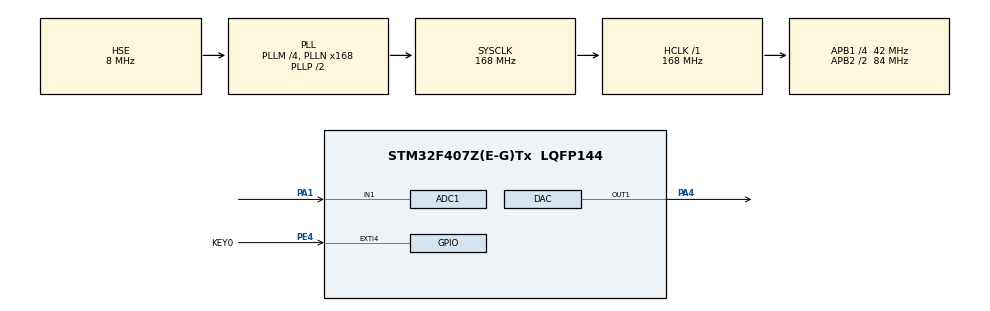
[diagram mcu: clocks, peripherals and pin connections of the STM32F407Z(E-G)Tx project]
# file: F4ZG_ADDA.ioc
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ADC1.Channel-5\#ChannelRegularConversion=ADC_CHANNEL_1
ADC1.NbrOfConversionFlag=1
ADC1.Rank-5\#ChannelRegularConversion=1
ADC1.SamplingTime-5\#ChannelRegularConversion=ADC_SAMPLETIME_3CYCLES
ADC1.master=1
Mcu.Family=STM32F4
Mcu.Name=STM32F407Z(E-G)Tx
Mcu.Package=LQFP144
NVIC.PriorityGroup=NVIC_PRIORITYGROUP_4
PA1.Signal=ADCx_IN1
PA13.Mode=Serial_Wire
PA13.Signal=SYS_JTMS-SWDIO
PA14.Mode=Serial_Wire
PA14.Signal=SYS_JTCK-SWCLK
PA4.Signal=COMP_DAC1_group
PE4.GPIO_Label=KEY0
PE4.GPIO_ModeDefaultEXTI=GPIO_MODE_IT_FALLING
PE4.GPIO_PuPd=GPIO_PULLUP
PE4.Signal=GPXTI4
PH0-OSC_IN.Mode=HSE-External-Oscillator
PH0-OSC_IN.Signal=RCC_OSC_IN
PH1-OSC_OUT.Mode=HSE-External-Oscillator
PH1-OSC_OUT.Signal=RCC_OSC_OUT
ProjectManager.HeapSize=0x200
ProjectManager.StackSize=0x400
ProjectManager.TargetToolchain=MDK-ARM V5
RCC.48MHZClocksFreq_Value=84000000
RCC.AHBFreq_Value=168000000
RCC.APB1CLKDivider=RCC_HCLK_DIV4
RCC.APB1Freq_Value=42000000
RCC.APB1TimFreq_Value=84000000
RCC.APB2CLKDivider=RCC_HCLK_DIV2
RCC.APB2Freq_Value=84000000
RCC.APB2TimFreq_Value=168000000
RCC.CortexFreq_Value=168000000
RCC.HCLKFreq_Value=168000000
RCC.HSE_VALUE=8000000
RCC.HSI_VALUE=16000000
RCC.PLLM=4
RCC.PLLN=168
RCC.PLLSourceVirtual=RCC_PLLSOURCE_HSE
RCC.SYSCLKFreq_VALUE=168000000
RCC.SYSCLKSource=RCC_SYSCLKSOURCE_PLLCLK
RCC.VCOOutputFreq_Value=336000000
SH.ADCx_IN1.0=ADC1_IN1,IN1
SH.COMP_DAC1_group.0=DAC_OUT1,DAC_OUT1
TIM2.Period=9
TIM2.Prescaler=20
VP_TIM2_VS_ClockSourceINT.Mode=Internal
board=custom

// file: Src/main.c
/* USER CODE BEGIN Header */
/**
  ******************************************************************************
  * @file           : main.c
  * @brief          : Main program body
  ******************************************************************************
  * @attention
  *
  * <h2><center>&copy; Copyright (c) 2021 STMicroelectronics.
  * All rights reserved.</center></h2>
  *
  * This software component is licensed by ST under BSD 3-Clause license,
  * the "License"; You may not use this file except in compliance with the
  * License. You may obtain a copy of the License at:
  *                        opensource.org/licenses/BSD-3-Clause
  *
  ******************************************************************************
  */
/* USER CODE END Header */

#include "main.h"
#include "adc.h"
#include "dac.h"
#include "tim.h"
#include "gpio.h"

void SystemClock_Config(void);

/* USER CODE BEGIN 0 */
uint32_t AD_1;

/* USER CODE END 0 */

int main(void)
{

  /* MCU Configuration--------------------------------------------------------*/

  /* Reset of all peripherals, Initializes the Flash interface and the Systick. */
  HAL_Init();

  /* Configure the system clock */
  SystemClock_Config();

  /* Initialize all configured peripherals */
  MX_GPIO_Init();
  MX_ADC1_Init();
  MX_DAC_Init();
  MX_TIM2_Init();
  /* USER CODE BEGIN 2 */
HAL_ADC_Start(&hadc1); //??ADC??
HAL_DAC_Start(&hdac,DAC_CHANNEL_1); //??DAC??

//HAL_ADC_Start_DMA(&hadc1,(uint32_t*)AD_1,1);
  /* USER CODE END 2 */

  /* Infinite loop */
  while (1)
  {

        AD_1 = get_AD1();
        HAL_Delay(500);
    /* USER CODE BEGIN */
  }
  /* USER CODE END 3 */
}

void SystemClock_Config(void)
{
  RCC_OscInitTypeDef RCC_OscInitStruct = {0};
  RCC_ClkInitTypeDef RCC_ClkInitStruct = {0};

  /** Configure the main internal regulator output voltage
  */
  __HAL_RCC_PWR_CLK_ENABLE();
  __HAL_PWR_VOLTAGESCALING_CONFIG(PWR_REGULATOR_VOLTAGE_SCALE1);
  /** Initializes the CPU, AHB and APB busses clocks
  */
  RCC_OscInitStruct.OscillatorType = RCC_OSCILLATORTYPE_HSE;
  RCC_OscInitStruct.HSEState = RCC_HSE_ON;
  RCC_OscInitStruct.PLL.PLLState = RCC_PLL_ON;
  RCC_OscInitStruct.PLL.PLLSource = RCC_PLLSOURCE_HSE;
  RCC_OscInitStruct.PLL.PLLM = 4;
  RCC_OscInitStruct.PLL.PLLN = 168;
  RCC_OscInitStruct.PLL.PLLP = RCC_PLLP_DIV2;
  RCC_OscInitStruct.PLL.PLLQ = 4;
  if (HAL_RCC_OscConfig(&RCC_OscInitStruct) != HAL_OK)
  {
    Error_Handler();
  }
  /** Initializes the CPU, AHB and APB busses clocks
  */
  RCC_ClkInitStruct.ClockType = RCC_CLOCKTYPE_HCLK|RCC_CLOCKTYPE_SYSCLK
                              |RCC_CLOCKTYPE_PCLK1|RCC_CLOCKTYPE_PCLK2;
  RCC_ClkInitStruct.SYSCLKSource = RCC_SYSCLKSOURCE_PLLCLK;
  RCC_ClkInitStruct.AHBCLKDivider = RCC_SYSCLK_DIV1;
  RCC_ClkInitStruct.APB1CLKDivider = RCC_HCLK_DIV4;
  RCC_ClkInitStruct.APB2CLKDivider = RCC_HCLK_DIV2;

  if (HAL_RCC_ClockConfig(&RCC_ClkInitStruct, FLASH_LATENCY_5) != HAL_OK)
  {
    Error_Handler();
  }
}

void Error_Handler(void)
{
}

/************************ (C) COPYRIGHT STMicroelectronics *****END OF FILE****/
